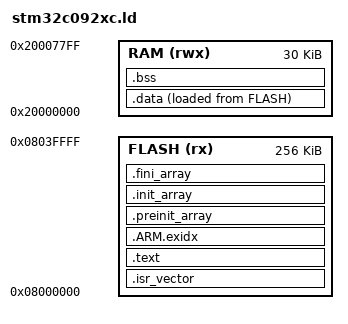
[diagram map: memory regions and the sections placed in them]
/*
 * Linker script for STM32C092FCP6.
 * 256 KB flash, 30 KB RAM (36 KB if the SRAM parity check is disabled).
 * Symbol names match ST's startup_stm32c092xx.s.
 */

ENTRY(Reset_Handler)

MEMORY
{
    FLASH (rx)  : ORIGIN = 0x08000000, LENGTH = 256K
    RAM   (rwx) : ORIGIN = 0x20000000, LENGTH = 30K
}

/* Initial stack pointer: top of RAM, the stack grows downwards */
_estack = ORIGIN(RAM) + LENGTH(RAM);

SECTIONS
{
    /* Interrupt vector table: must be first in flash */
    .isr_vector :
    {
        . = ALIGN(4);
        KEEP(*(.isr_vector))
        . = ALIGN(4);
    } > FLASH

    /* Code and constants */
    .text :
    {
        . = ALIGN(4);
        *(.text*)
        *(.rodata*)
        KEEP(*(.init))
        KEEP(*(.fini))
        . = ALIGN(4);
    } > FLASH

    .ARM.exidx :
    {
        *(.ARM.exidx*)
    } > FLASH

    /* Start-up function tables used by the C library */
    .preinit_array :
    {
        PROVIDE_HIDDEN(__preinit_array_start = .);
        KEEP(*(.preinit_array*))
        PROVIDE_HIDDEN(__preinit_array_end = .);
    } > FLASH

    .init_array :
    {
        PROVIDE_HIDDEN(__init_array_start = .);
        KEEP(*(SORT(.init_array.*)))
        KEEP(*(.init_array*))
        PROVIDE_HIDDEN(__init_array_end = .);
    } > FLASH

    .fini_array :
    {
        PROVIDE_HIDDEN(__fini_array_start = .);
        KEEP(*(SORT(.fini_array.*)))
        KEEP(*(.fini_array*))
        PROVIDE_HIDDEN(__fini_array_end = .);
    } > FLASH

    /* Initialised variables: stored in flash, copied to RAM at start-up */
    _sidata = LOADADDR(.data);

    .data :
    {
        . = ALIGN(4);
        _sdata = .;
        *(.data*)
        . = ALIGN(4);
        _edata = .;
    } > RAM AT > FLASH

    /* Zero-initialised variables */
    .bss (NOLOAD) :
    {
        . = ALIGN(4);
        _sbss = .;
        __bss_start__ = _sbss;
        *(.bss*)
        *(COMMON)
        . = ALIGN(4);
        _ebss = .;
        __bss_end__ = _ebss;
    } > RAM

    /* Start of the (unused) heap, wanted by the C library */
    PROVIDE(end = _ebss);
    PROVIDE(_end = _ebss);
}
